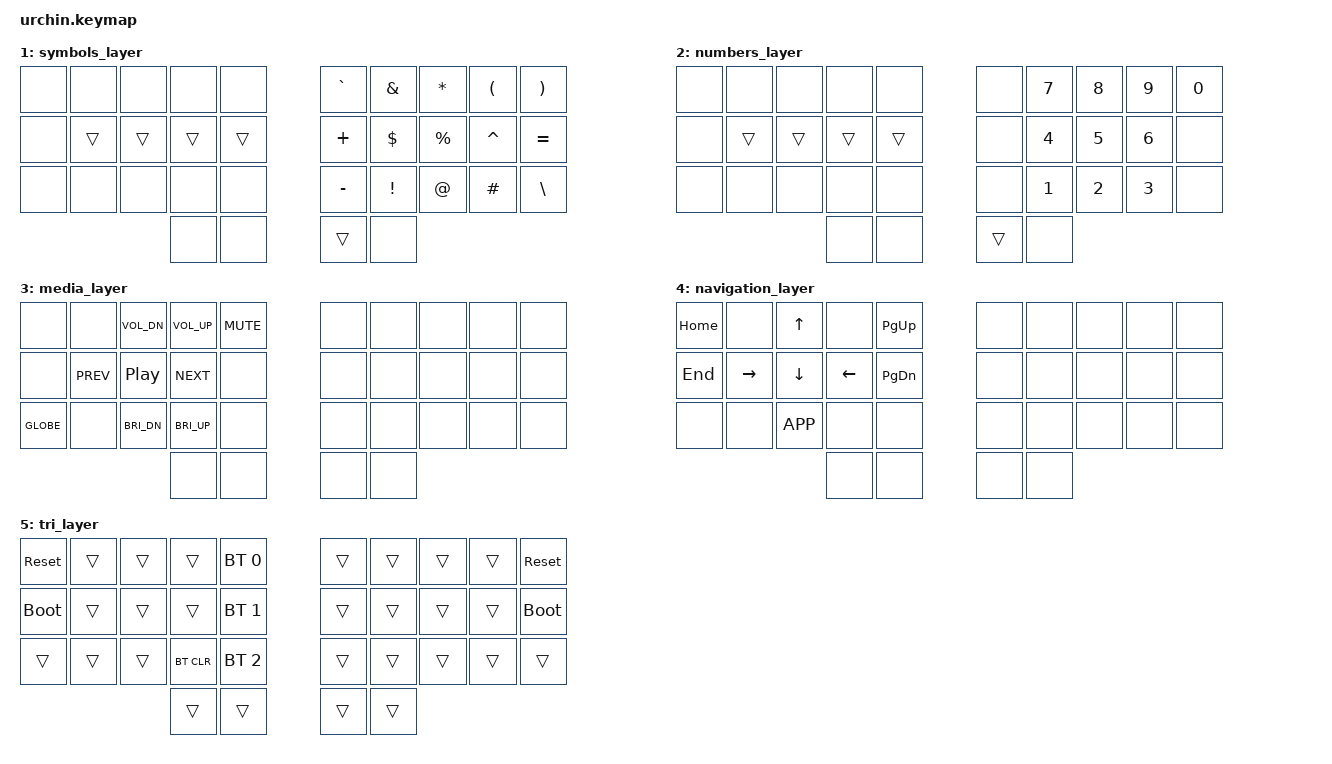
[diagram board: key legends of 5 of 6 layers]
// Copyright (c) 2022 The ZMK Contributors
// SPDX-License-Identifier: MIT

#include <behaviors.dtsi>
#include <dt-bindings/zmk/keys.h>
#include <dt-bindings/zmk/bt.h>


// Home row mods macro
#define HRML(k1,k2,k3,k4) &hrm LALT k1  &hrm LSHFT k2  &hrm LCTRL k3  &hrm LGUI k4
#define HRMR(k1,k2,k3,k4) &hrm RGUI k1 &hrm RCTRL k2  &hrm RSHFT k3  &hrm RALT k4

/ {
    behaviors {
        hrm: home_row_mod {
            compatible = "zmk,behavior-hold-tap";
            #binding-cells = <2>;
            flavor = "balanced";
            tapping-term-ms = <220>;
            quick-tap-ms = <150>;
            require-prior-idle-ms = <100>;
            bindings = <&kp>, <&kp>;
        };

        retm: return_m {
            compatible = "zmk,behavior-mod-morph";
            #binding-cells = <0>;
            bindings = <&kp M>, <&kp RETURN>;
            mods = <(MOD_LCTL)>;
        };
        tabi: tab_i {
            compatible = "zmk,behavior-mod-morph";
            #binding-cells = <0>;
            bindings = <&kp I>, <&kp TAB>;
            mods = <(MOD_LCTL)>;
        };
        bspch: backspace_h {
            compatible = "zmk,behavior-mod-morph";
            #binding-cells = <0>;
            bindings = <&kp H>, <&kp BSPC>;
            mods = <(MOD_LCTL)>;
        };
        escsem: escape_semi {
            compatible = "zmk,behavior-mod-morph";
            #binding-cells = <0>;
            bindings = <&kp SEMI>, <&kp ESC>;
            mods = <(MOD_LCTL)>;
        };
    };


    combos {
        compatible = "zmk,combos";

        combo_esc {
            timeout-ms = <50>;
            key-positions = <1 2>; // W + E
            bindings = <&kp ESC>;
        };

        combo_tab {
            timeout-ms = <50>;
            key-positions = <10 11>; // A + S
            bindings = <&kp TAB>;
        };

        combo_enter {
            timeout-ms = <350>;
            key-positions = <18 19>; // L + ;
            bindings = <&kp ENTER>;
        };

        combo_enter_2 {
            timeout-ms = <350>;
            key-positions = <27 28>; // , + .
            bindings = <&kp ENTER>;
        };

        combo_bspc {
            timeout-ms = <350>;
            key-positions = <7 8>; // I + O
            bindings = <&kp BSPC>;
        };

        combo_caps_word {
            timeout-ms = <50>;
            key-positions = <10 19>; // A + ;
            bindings = <&caps_word>; 
        };

	combo_settings {
	    timeout-ms = <200>;
	    key-positions = <30 31>;
	    bindings = <&mo 5>;
	};
    };

    keymap {
        compatible = "zmk,keymap";
        default_layer { // 0
            bindings = <
        //╭──────────┬──────────┬──────────┬──────────┬──────────╮   ╭──────────┬──────────┬──────────┬──────────┬──────────╮
        //│  Q       │  W       │  E       │  R       │  T       │   │  Y       │  U       │  I       │  O       │  P       │
            &kp Q      &kp W      &kp E      &kp R      &kp T          &kp Y      &kp U      &tabi      &kp O      &kp P
        //├──────────┼──────────┼──────────┼──────────┼──────────┤   ├──────────┼──────────┼──────────┼──────────┼──────────┤
        //│  A       │  S       │  D       │  F       │  G       │   │  H       │  J       │  K       │  L       │  ;       │
            &kp A      HRML(S,     D,         F,         G)           HRMR(H,      J,         K,         L)       &escsem
        //├──────────┼──────────┼──────────┼──────────┼──────────┤   ├──────────┼──────────┼──────────┼──────────┼──────────┤
        //│  Z       │  X       │  C       │  V       │  B       │   │  N       │  M       │ , <      │ . >      │ / ?      │
            &kp Z      &kp X      &kp C      &kp V      &kp B          &kp N      &retm      &kp COMMA  &kp DOT    &kp FSLH
        //╰──────────┴──────────┴──────────┼──────────┼──────────┤   ├──────────┼──────────┼──────────┴──────────┴──────────╯
                                            &lt 2 LBKT &lt 1 SQT      &lt 3 SPC  &lt 4 RBKT
        //                                 ╰──────────┴──────────╯   ╰──────────┴──────────╯
            >;
        };

        symbols_layer { // 1
            bindings = <
        //╭──────────┬──────────┬──────────┬──────────┬──────────╮   ╭──────────┬──────────┬──────────┬──────────┬──────────╮
        //│          │          │          │          │          │   │  `       │  &       │  *       │  (       │  )       │
            &none      &none      &none      &none      &none          &kp GRAVE  &kp AMPS   &kp ASTRK  &kp LPAR   &kp RPAR
        //├──────────┼──────────┼──────────┼──────────┼──────────┤   ├──────────┼──────────┼──────────┼──────────┼──────────┤
        //│          │          │          │          │          │   │  +       │  $       │  %       │  ^       │  =       │
            &none      &trans     &trans     &trans     &trans         &kp PLUS   &kp DLLR   &kp PRCNT  &kp CARET  &kp EQUAL
        //├──────────┼──────────┼──────────┼──────────┼──────────┤   ├──────────┼──────────┼──────────┼──────────┼──────────┤
        //│          │          │          │          │          │   │  -       │  !       │  @       │  #       │  \       │
            &none      &none      &none      &none      &none          &kp MINUS  &kp EXCL   &kp AT     &kp HASH   &kp BSLH 
        //╰──────────┴──────────┴──────────┼──────────┼──────────┤   ├──────────┼──────────┼──────────┴──────────┴──────────╯
                                             &none      &none          &trans     &none 
        //                                 ╰──────────┴──────────╯   ╰──────────┴──────────╯
            >;
        };

        numbers_layer { // 2
            bindings = <
        //╭──────────┬──────────┬──────────┬──────────┬──────────╮   ╭──────────┬──────────┬──────────┬──────────┬──────────╮
        //│          │          │          │          │          │   │          │  7       │  8       │  9       │  0       │
            &none      &none      &none      &none      &none          &none      &kp N7     &kp N8     &kp N9     &kp N0   
        //├──────────┼──────────┼──────────┼──────────┼──────────┤   ├──────────┼──────────┼──────────┼──────────┼──────────┤
        //│          │          │          │          │          │   │          │  4       │  5       │  6       │          │
            &none      &trans     &trans     &trans     &trans         &none      &kp N4     &kp N5     &kp N6     &none
        //├──────────┼──────────┼──────────┼──────────┼──────────┤   ├──────────┼──────────┼──────────┼──────────┼──────────┤
        //│          │          │          │          │          │   │          │  1       │  2       │  3       │          │
           &none       &none      &none      &none      &none          &none      &kp N1     &kp N2     &kp N3     &none
        //╰──────────┴──────────┴──────────┼──────────┼──────────┤   ├──────────┼──────────┼──────────┴──────────┴──────────╯
                                             &none      &none          &trans     &none 
        //                                 ╰──────────┴──────────╯   ╰──────────┴──────────╯
            >;
        };

        media_layer { // 3
            bindings = <
        //╭──────────┬──────────┬──────────┬──────────┬──────────╮   ╭──────────┬──────────┬──────────┬──────────┬──────────╮
        //│          │          │          │          │          │   │          │          │          │          │          │
            &none      &none  &kp C_VOL_DN &kp C_VOL_UP &kp C_MUTE         &none      &none      &none      &none      &none   
        //├──────────┼──────────┼──────────┼──────────┼──────────┤   ├──────────┼──────────┼──────────┼──────────┼──────────┤
        //│          │          │          │          │          │   │          │          │          │          │          │
            &none      &kp C_PREV &kp C_PP  &kp C_NEXT  &none          &none      &none      &none      &none      &none
        //├──────────┼──────────┼──────────┼──────────┼──────────┤   ├──────────┼──────────┼──────────┼──────────┼──────────┤
        //│          │          │          │          │          │   │          │          │          │          │          │
           &kp GLOBE  &none     &kp C_BRI_DN &kp C_BRI_UP  &none          &none      &none      &none      &none      &none
        //╰──────────┴──────────┴──────────┼──────────┼──────────┤   ├──────────┼──────────┼──────────┴──────────┴──────────╯
                                             &none      &none          &none     &none
        //                                 ╰──────────┴──────────╯   ╰──────────┴──────────╯
            >;
        };
        
        navigation_layer { // 4
            bindings = <
        //╭──────────┬──────────┬──────────┬──────────┬──────────╮   ╭──────────┬──────────┬──────────┬──────────┬──────────╮
        //│          │          │          │          │          │   │          │          │          │          │          │
            &kp HOME   &none      &kp UP     &none      &kp PG_UP      &none      &none      &none      &none      &none   
        //├──────────┼──────────┼──────────┼──────────┼──────────┤   ├──────────┼──────────┼──────────┼──────────┼──────────┤
        //│          │          │          │          │          │   │          │          │          │          │          │
            &kp END    &kp RIGHT  &kp DOWN   &kp LEFT   &kp PG_DN      &none      &none      &none      &none      &none
        //├──────────┼──────────┼──────────┼──────────┼──────────┤   ├──────────┼──────────┼──────────┼──────────┼──────────┤
        //│          │          │          │          │          │   │          │          │          │          │          │
            &none      &none      &kp K_APP  &none      &none          &none      &none      &none      &none      &none
        //╰──────────┴──────────┴──────────┼──────────┼──────────┤   ├──────────┼──────────┼──────────┴──────────┴──────────╯
                                             &none      &none          &none     &none
        //                                 ╰──────────┴──────────╯   ╰──────────┴──────────╯
            >;
        };



        tri_layer { // 5
            bindings = <
        //╭──────────┬──────────┬──────────┬──────────┬──────────╮   ╭──────────┬──────────┬──────────┬──────────┬──────────╮
        //│ RESET    │          │          │          │PROFILE 0 │   │          │          │          │          │  RESET   │
           &sys_reset  &trans     &trans    &trans    &bt BT_SEL 0     &trans     &trans     &trans     &trans    &sys_reset
        //├──────────┼──────────┼──────────┼──────────┼──────────┤   ├──────────┼──────────┼──────────┼──────────┼──────────┤
        //│BOOTLOADER│          │          │          │PROFILE 1 │   │          │          │          │          │BOOTLOADER│
          &bootloader  &trans     &trans     &trans    &bt BT_SEL 1    &trans     &trans     &trans     &trans    &bootloader
        //├──────────┼──────────┼──────────┼──────────┼──────────┤   ├──────────┼──────────┼──────────┼──────────┼──────────┤
        //│          │          │          │ CLEAR BT │PROFILE 2 │   │          │          │          │          │          │
            &trans     &trans     &trans    &bt BT_CLR &bt BT_SEL 2    &trans     &trans     &trans     &trans     &trans
        //╰──────────┴──────────┴──────────┼──────────┼──────────┤   ├──────────┼──────────┼──────────┴──────────┴──────────╯
                                             &trans     &trans         &trans     &trans
        //                                 ╰──────────┴──────────╯   ╰──────────┴──────────╯
            >;
        };
    };
};
